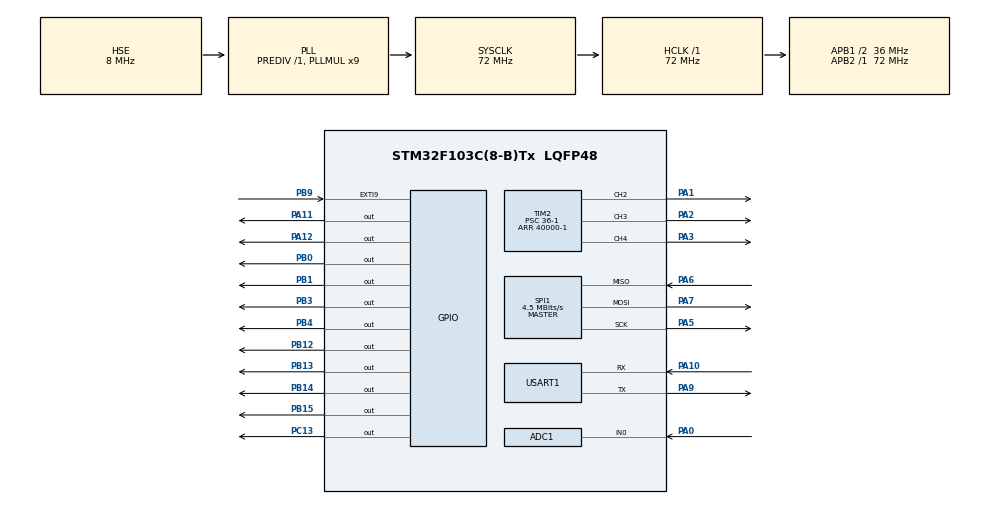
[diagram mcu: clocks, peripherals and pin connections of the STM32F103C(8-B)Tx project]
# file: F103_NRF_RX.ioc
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ADC1.Channel-0\#ChannelRegularConversion=ADC_CHANNEL_0
ADC1.NbrOfConversionFlag=1
ADC1.Rank-0\#ChannelRegularConversion=1
ADC1.SamplingTime-0\#ChannelRegularConversion=ADC_SAMPLETIME_1CYCLE_5
ADC1.master=1
Dma.ADC1.0.Direction=DMA_PERIPH_TO_MEMORY
Dma.ADC1.0.Instance=DMA1_Channel1
Dma.ADC1.0.MemDataAlignment=DMA_MDATAALIGN_HALFWORD
Dma.ADC1.0.MemInc=DMA_MINC_ENABLE
Dma.ADC1.0.Mode=DMA_NORMAL
Dma.ADC1.0.PeriphDataAlignment=DMA_PDATAALIGN_HALFWORD
Dma.ADC1.0.PeriphInc=DMA_PINC_DISABLE
Dma.ADC1.0.Priority=DMA_PRIORITY_LOW
Dma.Request0=ADC1
Mcu.Family=STM32F1
Mcu.Name=STM32F103C(8-B)Tx
Mcu.Package=LQFP48
NVIC.DMA1_Channel1_IRQn=true\:0\:0\:false\:false\:true\:false\:true
NVIC.EXTI9_5_IRQn=true\:0\:0\:false\:false\:true\:true\:true
NVIC.PriorityGroup=NVIC_PRIORITYGROUP_4
NVIC.TIM1_UP_IRQn=true\:0\:0\:false\:false\:true\:true\:true
PA0-WKUP.Signal=ADCx_IN0
PA1.Signal=S_TIM2_CH2
PA10.Mode=Asynchronous
PA10.Signal=USART1_RX
PA11.Signal=GPIO_Output
PA12.Signal=GPIO_Output
PA13.Mode=Serial_Wire
PA13.Signal=SYS_JTMS-SWDIO
PA14.Mode=Serial_Wire
PA14.Signal=SYS_JTCK-SWCLK
PA2.Signal=S_TIM2_CH3
PA3.Signal=S_TIM2_CH4
PA5.Mode=Full_Duplex_Master
PA5.Signal=SPI1_SCK
PA6.Mode=Full_Duplex_Master
PA6.Signal=SPI1_MISO
PA7.Mode=Full_Duplex_Master
PA7.Signal=SPI1_MOSI
PA9.Mode=Asynchronous
PA9.Signal=USART1_TX
PB0.Signal=GPIO_Output
PB1.Signal=GPIO_Output
PB12.Signal=GPIO_Output
PB13.Signal=GPIO_Output
PB14.Signal=GPIO_Output
PB15.Signal=GPIO_Output
PB3.Signal=GPIO_Output
PB4.Signal=GPIO_Output
PB9.GPIO_PuPd=GPIO_PULLDOWN
PB9.Signal=GPXTI9
PC13-TAMPER-RTC.Signal=GPIO_Output
PD0-OSC_IN.Mode=HSE-External-Oscillator
PD0-OSC_IN.Signal=RCC_OSC_IN
PD1-OSC_OUT.Mode=HSE-External-Oscillator
PD1-OSC_OUT.Signal=RCC_OSC_OUT
ProjectManager.HeapSize=0x200
ProjectManager.StackSize=0x400
ProjectManager.TargetToolchain=EWARM V8.32
RCC.ADCPresc=RCC_ADCPCLK2_DIV6
RCC.AHBFreq_Value=72000000
RCC.APB1CLKDivider=RCC_HCLK_DIV2
RCC.APB1Freq_Value=36000000
RCC.APB1TimFreq_Value=72000000
RCC.APB2Freq_Value=72000000
RCC.APB2TimFreq_Value=72000000
RCC.HCLKFreq_Value=72000000
RCC.PLLMUL=RCC_PLL_MUL9
RCC.PLLSourceVirtual=RCC_PLLSOURCE_HSE
RCC.SYSCLKFreq_VALUE=72000000
RCC.SYSCLKSource=RCC_SYSCLKSOURCE_PLLCLK
RCC.USBFreq_Value=72000000
SH.ADCx_IN0.0=ADC1_IN0,IN0
SH.S_TIM2_CH2.0=TIM2_CH2,PWM Generation2 CH2
SH.S_TIM2_CH3.0=TIM2_CH3,PWM Generation3 CH3
SH.S_TIM2_CH4.0=TIM2_CH4,PWM Generation4 CH4
SPI1.BaudRatePrescaler=SPI_BAUDRATEPRESCALER_16
SPI1.CalculateBaudRate=4.5 MBits/s
SPI1.Direction=SPI_DIRECTION_2LINES
SPI1.Mode=SPI_MODE_MASTER
SPI1.VirtualType=VM_MASTER
TIM1.Period=9
TIM1.Prescaler=7199
TIM2.Channel-PWM\ Generation2\ CH2=TIM_CHANNEL_2
TIM2.Channel-PWM\ Generation3\ CH3=TIM_CHANNEL_3
TIM2.Channel-PWM\ Generation4\ CH4=TIM_CHANNEL_4
TIM2.Period=40000-1
TIM2.Prescaler=36-1
USART1.VirtualMode=VM_ASYNC
VP_TIM1_VS_ClockSourceINT.Mode=Internal
board=custom

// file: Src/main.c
/* USER CODE BEGIN Header */
/**
  ******************************************************************************
  * @file           : main.c
  * @brief          : Main program body
  ******************************************************************************
  * @attention
  *
  * <h2><center>&copy; Copyright (c) 2021 STMicroelectronics.
  * All rights reserved.</center></h2>
  *
  * This software component is licensed by ST under BSD 3-Clause license,
  * the "License"; You may not use this file except in compliance with the
  * License. You may obtain a copy of the License at:
  *                        opensource.org/licenses/BSD-3-Clause
  *
  ******************************************************************************
  */
/* USER CODE END Header */

#include "main.h"

/* USER CODE BEGIN Includes */
#include "logic.h"
#include "nrf24.h"
/* USER CODE END Includes */

ADC_HandleTypeDef hadc1;
DMA_HandleTypeDef hdma_adc1;

SPI_HandleTypeDef hspi1;

TIM_HandleTypeDef htim1;
TIM_HandleTypeDef htim2;

UART_HandleTypeDef huart1;

void SystemClock_Config(void);
static void MX_GPIO_Init(void);
static void MX_DMA_Init(void);
static void MX_SPI1_Init(void);
static void MX_TIM1_Init(void);
static void MX_ADC1_Init(void);
static void MX_TIM2_Init(void);
static void MX_USART1_UART_Init(void);
/* USER CODE BEGIN PFP */
void runRadio(void);
/* USER CODE END PFP */

int main(void)
{

  /* MCU Configuration--------------------------------------------------------*/

  /* Reset of all peripherals, Initializes the Flash interface and the Systick. */
  HAL_Init();

  /* Configure the system clock */
  SystemClock_Config();

  /* Initialize all configured peripherals */
  MX_GPIO_Init();
  MX_DMA_Init();
  MX_SPI1_Init();
  MX_TIM1_Init();
  MX_ADC1_Init();
  MX_TIM2_Init();
  MX_USART1_UART_Init();
  /* USER CODE BEGIN 2 */
  LOGICstart();

  /* USER CODE END 2 */

  /* Infinite loop */
  /* USER CODE BEGIN WHILE */
  while (1)
  {
    LOGIC();

    /* USER CODE END WHILE */

  }
}

void SystemClock_Config(void)
{
  RCC_OscInitTypeDef RCC_OscInitStruct = {0};
  RCC_ClkInitTypeDef RCC_ClkInitStruct = {0};
  RCC_PeriphCLKInitTypeDef PeriphClkInit = {0};

  /** Initializes the CPU, AHB and APB busses clocks
  */
  RCC_OscInitStruct.OscillatorType = RCC_OSCILLATORTYPE_HSE;
  RCC_OscInitStruct.HSEState = RCC_HSE_ON;
  RCC_OscInitStruct.HSEPredivValue = RCC_HSE_PREDIV_DIV1;
  RCC_OscInitStruct.HSIState = RCC_HSI_ON;
  RCC_OscInitStruct.PLL.PLLState = RCC_PLL_ON;
  RCC_OscInitStruct.PLL.PLLSource = RCC_PLLSOURCE_HSE;
  RCC_OscInitStruct.PLL.PLLMUL = RCC_PLL_MUL9;
  if (HAL_RCC_OscConfig(&RCC_OscInitStruct) != HAL_OK)
  {
    Error_Handler();
  }
  /** Initializes the CPU, AHB and APB busses clocks
  */
  RCC_ClkInitStruct.ClockType = RCC_CLOCKTYPE_HCLK|RCC_CLOCKTYPE_SYSCLK
                              |RCC_CLOCKTYPE_PCLK1|RCC_CLOCKTYPE_PCLK2;
  RCC_ClkInitStruct.SYSCLKSource = RCC_SYSCLKSOURCE_PLLCLK;
  RCC_ClkInitStruct.AHBCLKDivider = RCC_SYSCLK_DIV1;
  RCC_ClkInitStruct.APB1CLKDivider = RCC_HCLK_DIV2;
  RCC_ClkInitStruct.APB2CLKDivider = RCC_HCLK_DIV1;

  if (HAL_RCC_ClockConfig(&RCC_ClkInitStruct, FLASH_LATENCY_2) != HAL_OK)
  {
    Error_Handler();
  }
  PeriphClkInit.PeriphClockSelection = RCC_PERIPHCLK_ADC;
  PeriphClkInit.AdcClockSelection = RCC_ADCPCLK2_DIV6;
  if (HAL_RCCEx_PeriphCLKConfig(&PeriphClkInit) != HAL_OK)
  {
    Error_Handler();
  }
}

static void MX_ADC1_Init(void)
{

  ADC_ChannelConfTypeDef sConfig = {0};

  /** Common config
  */
  hadc1.Instance = ADC1;
  hadc1.Init.ScanConvMode = ADC_SCAN_DISABLE;
  hadc1.Init.ContinuousConvMode = DISABLE;
  hadc1.Init.DiscontinuousConvMode = DISABLE;
  hadc1.Init.ExternalTrigConv = ADC_SOFTWARE_START;
  hadc1.Init.DataAlign = ADC_DATAALIGN_RIGHT;
  hadc1.Init.NbrOfConversion = 1;
  if (HAL_ADC_Init(&hadc1) != HAL_OK)
  {
    Error_Handler();
  }
  /** Configure Regular Channel
  */
  sConfig.Channel = ADC_CHANNEL_0;
  sConfig.Rank = ADC_REGULAR_RANK_1;
  sConfig.SamplingTime = ADC_SAMPLETIME_1CYCLE_5;
  if (HAL_ADC_ConfigChannel(&hadc1, &sConfig) != HAL_OK)
  {
    Error_Handler();
  }

}

static void MX_SPI1_Init(void)
{

  /* SPI1 parameter configuration*/
  hspi1.Instance = SPI1;
  hspi1.Init.Mode = SPI_MODE_MASTER;
  hspi1.Init.Direction = SPI_DIRECTION_2LINES;
  hspi1.Init.DataSize = SPI_DATASIZE_8BIT;
  hspi1.Init.CLKPolarity = SPI_POLARITY_LOW;
  hspi1.Init.CLKPhase = SPI_PHASE_1EDGE;
  hspi1.Init.NSS = SPI_NSS_SOFT;
  hspi1.Init.BaudRatePrescaler = SPI_BAUDRATEPRESCALER_16;
  hspi1.Init.FirstBit = SPI_FIRSTBIT_MSB;
  hspi1.Init.TIMode = SPI_TIMODE_DISABLE;
  hspi1.Init.CRCCalculation = SPI_CRCCALCULATION_DISABLE;
  hspi1.Init.CRCPolynomial = 10;
  if (HAL_SPI_Init(&hspi1) != HAL_OK)
  {
    Error_Handler();
  }

}

static void MX_TIM1_Init(void)
{

  TIM_ClockConfigTypeDef sClockSourceConfig = {0};
  TIM_MasterConfigTypeDef sMasterConfig = {0};

  htim1.Instance = TIM1;
  htim1.Init.Prescaler = 7199;
  htim1.Init.CounterMode = TIM_COUNTERMODE_UP;
  htim1.Init.Period = 9;
  htim1.Init.ClockDivision = TIM_CLOCKDIVISION_DIV1;
  htim1.Init.RepetitionCounter = 0;
  htim1.Init.AutoReloadPreload = TIM_AUTORELOAD_PRELOAD_DISABLE;
  if (HAL_TIM_Base_Init(&htim1) != HAL_OK)
  {
    Error_Handler();
  }
  sClockSourceConfig.ClockSource = TIM_CLOCKSOURCE_INTERNAL;
  if (HAL_TIM_ConfigClockSource(&htim1, &sClockSourceConfig) != HAL_OK)
  {
    Error_Handler();
  }
  sMasterConfig.MasterOutputTrigger = TIM_TRGO_RESET;
  sMasterConfig.MasterSlaveMode = TIM_MASTERSLAVEMODE_DISABLE;
  if (HAL_TIMEx_MasterConfigSynchronization(&htim1, &sMasterConfig) != HAL_OK)
  {
    Error_Handler();
  }

}

static void MX_TIM2_Init(void)
{

  TIM_MasterConfigTypeDef sMasterConfig = {0};
  TIM_OC_InitTypeDef sConfigOC = {0};

  htim2.Instance = TIM2;
  htim2.Init.Prescaler = 36-1;
  htim2.Init.CounterMode = TIM_COUNTERMODE_UP;
  htim2.Init.Period = 40000-1;
  htim2.Init.ClockDivision = TIM_CLOCKDIVISION_DIV1;
  htim2.Init.AutoReloadPreload = TIM_AUTORELOAD_PRELOAD_DISABLE;
  if (HAL_TIM_PWM_Init(&htim2) != HAL_OK)
  {
    Error_Handler();
  }
  sMasterConfig.MasterOutputTrigger = TIM_TRGO_RESET;
  sMasterConfig.MasterSlaveMode = TIM_MASTERSLAVEMODE_DISABLE;
  if (HAL_TIMEx_MasterConfigSynchronization(&htim2, &sMasterConfig) != HAL_OK)
  {
    Error_Handler();
  }
  sConfigOC.OCMode = TIM_OCMODE_PWM1;
  sConfigOC.Pulse = 0;
  sConfigOC.OCPolarity = TIM_OCPOLARITY_HIGH;
  sConfigOC.OCFastMode = TIM_OCFAST_DISABLE;
  if (HAL_TIM_PWM_ConfigChannel(&htim2, &sConfigOC, TIM_CHANNEL_2) != HAL_OK)
  {
    Error_Handler();
  }
  if (HAL_TIM_PWM_ConfigChannel(&htim2, &sConfigOC, TIM_CHANNEL_3) != HAL_OK)
  {
    Error_Handler();
  }
  if (HAL_TIM_PWM_ConfigChannel(&htim2, &sConfigOC, TIM_CHANNEL_4) != HAL_OK)
  {
    Error_Handler();
  }
  HAL_TIM_MspPostInit(&htim2);

}

static void MX_USART1_UART_Init(void)
{

  huart1.Instance = USART1;
  huart1.Init.BaudRate = 115200;
  huart1.Init.WordLength = UART_WORDLENGTH_8B;
  huart1.Init.StopBits = UART_STOPBITS_1;
  huart1.Init.Parity = UART_PARITY_NONE;
  huart1.Init.Mode = UART_MODE_TX_RX;
  huart1.Init.HwFlowCtl = UART_HWCONTROL_NONE;
  huart1.Init.OverSampling = UART_OVERSAMPLING_16;
  if (HAL_UART_Init(&huart1) != HAL_OK)
  {
    Error_Handler();
  }

}

static void MX_DMA_Init(void)
{

  /* DMA controller clock enable */
  __HAL_RCC_DMA1_CLK_ENABLE();

  /* DMA interrupt init */
  /* DMA1_Channel1_IRQn interrupt configuration */
  HAL_NVIC_SetPriority(DMA1_Channel1_IRQn, 0, 0);
  HAL_NVIC_EnableIRQ(DMA1_Channel1_IRQn);

}

static void MX_GPIO_Init(void)
{
  GPIO_InitTypeDef GPIO_InitStruct = {0};

  /* GPIO Ports Clock Enable */
  __HAL_RCC_GPIOC_CLK_ENABLE();
  __HAL_RCC_GPIOD_CLK_ENABLE();
  __HAL_RCC_GPIOA_CLK_ENABLE();
  __HAL_RCC_GPIOB_CLK_ENABLE();

  /*Configure GPIO pin Output Level */
  HAL_GPIO_WritePin(GPIOC, GPIO_PIN_13, GPIO_PIN_RESET);

  /*Configure GPIO pin Output Level */
  HAL_GPIO_WritePin(GPIOB, GPIO_PIN_0|GPIO_PIN_1|GPIO_PIN_12|GPIO_PIN_13
                          |GPIO_PIN_14|GPIO_PIN_3|GPIO_PIN_4, GPIO_PIN_RESET);

  /*Configure GPIO pin Output Level */
  HAL_GPIO_WritePin(GPIOA, GPIO_PIN_11|GPIO_PIN_12, GPIO_PIN_RESET);

  /*Configure GPIO pin : PC13 */
  GPIO_InitStruct.Pin = GPIO_PIN_13;
  GPIO_InitStruct.Mode = GPIO_MODE_OUTPUT_PP;
  GPIO_InitStruct.Pull = GPIO_NOPULL;
  GPIO_InitStruct.Speed = GPIO_SPEED_FREQ_LOW;
  HAL_GPIO_Init(GPIOC, &GPIO_InitStruct);

  /*Configure GPIO pins : PB0 PB1 PB12 PB13
                           PB14 PB3 PB4 */
  GPIO_InitStruct.Pin = GPIO_PIN_0|GPIO_PIN_1|GPIO_PIN_12|GPIO_PIN_13
                          |GPIO_PIN_14|GPIO_PIN_15|GPIO_PIN_3|GPIO_PIN_4;
  GPIO_InitStruct.Mode = GPIO_MODE_OUTPUT_PP;
  GPIO_InitStruct.Pull = GPIO_NOPULL;
  GPIO_InitStruct.Speed = GPIO_SPEED_FREQ_LOW;
  HAL_GPIO_Init(GPIOB, &GPIO_InitStruct);

  /*Configure GPIO pins : PA11 PA12 */
  GPIO_InitStruct.Pin = GPIO_PIN_11|GPIO_PIN_12;
  GPIO_InitStruct.Mode = GPIO_MODE_OUTPUT_PP;
  GPIO_InitStruct.Pull = GPIO_NOPULL;
  GPIO_InitStruct.Speed = GPIO_SPEED_FREQ_LOW;
  HAL_GPIO_Init(GPIOA, &GPIO_InitStruct);

  /*Configure GPIO pin : PB9 */
  GPIO_InitStruct.Pin = GPIO_PIN_9;
  GPIO_InitStruct.Mode = GPIO_MODE_IT_RISING;
  GPIO_InitStruct.Pull = GPIO_PULLDOWN;
  HAL_GPIO_Init(GPIOB, &GPIO_InitStruct);

  /* EXTI interrupt init*/
  HAL_NVIC_SetPriority(EXTI9_5_IRQn, 0, 0);
  HAL_NVIC_EnableIRQ(EXTI9_5_IRQn);

}

void Error_Handler(void)
{
}

/************************ (C) COPYRIGHT STMicroelectronics *****END OF FILE****/
